# TM4C123BH6ZRB register map
Vendor: Texas Instruments; Series: TM4C; File version: 11073
CPU: CM4 r1p2, little endian, MPU, FPU, 3 interrupt priority bits
Registers are 32-bit, read-write, no defined reset value unless marked. A register's access mark holds for its fields unless they carry their own. Offsets are from the block's base; [hi:lo] are bit positions.

## WATCHDOG0 — Register map for WATCHDOG0 peripheral
Base 0x40000000; register names take the prefix WATCHDOG0
Same registers: WATCHDOG1 0x40001000 (register names take the prefix WATCHDOG1)
0x00 LOAD — Watchdog Load
  [31:0] WDT_LOAD — Watchdog Load Value
0x04 VALUE — Watchdog Value
  [31:0] WDT_VALUE
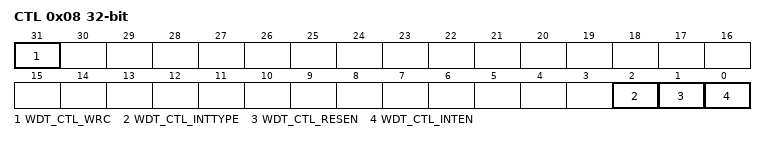
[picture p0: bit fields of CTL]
0x08 CTL — Watchdog Control
  [31] WDT_CTL_WRC — Write Complete
  [2] WDT_CTL_INTTYPE — Watchdog Interrupt Type
  [1] WDT_CTL_RESEN — Watchdog Reset Enable
  [0] WDT_CTL_INTEN — Watchdog Interrupt Enable
0x0C ICR wo — Watchdog Interrupt Clear
  [31:0] WDT_ICR
0x10 RIS — Watchdog Raw Interrupt Status
  [0] WDT_RIS_WDTRIS
0x14 MIS — Watchdog Masked Interrupt Status
  [0] WDT_MIS_WDTMIS
0x418 TEST — Watchdog Test
  [8] WDT_TEST_STALL — Watchdog Stall Enable
0xC00 LOCK — Watchdog Lock
  [31:0] WDT_LOCK
    0=WDT_LOCK_UNLOCKED (Unlocked); 1=WDT_LOCK_LOCKED (Locked); 0x1ACCE551=WDT_LOCK_UNLOCK (Unlocks the watchdog timer)

## GPIOA — Register map for GPIOA peripheral
Base 0x40004000; register names take the prefix GPIOA
Same registers: GPIOB 0x40005000 (register names take the prefix GPIOB), GPIOC 0x40006000 (register names take the prefix GPIOC), GPIOD 0x40007000 (register names take the prefix GPIOD), GPIOE 0x40024000 (register names take the prefix GPIOE), GPIOF 0x40025000 (register names take the prefix GPIOF), GPIOG 0x40026000 (register names take the prefix GPIOG), GPIOH 0x40027000 (register names take the prefix GPIOH), GPIOJ 0x4003D000 (register names take the prefix GPIOJ), GPIOA_AHB 0x40058000 (register names take the prefix GPIOA_AHB), GPIOB_AHB 0x40059000 (register names take the prefix GPIOB_AHB), GPIOC_AHB 0x4005A000 (register names take the prefix GPIOC_AHB), GPIOD_AHB 0x4005B000 (register names take the prefix GPIOD_AHB), GPIOE_AHB 0x4005C000 (register names take the prefix GPIOE_AHB), GPIOF_AHB 0x4005D000 (register names take the prefix GPIOF_AHB), GPIOG_AHB 0x4005E000 (register names take the prefix GPIOG_AHB), GPIOH_AHB 0x4005F000 (register names take the prefix GPIOH_AHB), GPIOJ_AHB 0x40060000 (register names take the prefix GPIOJ_AHB), GPIOK 0x40061000 (register names take the prefix GPIOK), GPIOL 0x40062000 (register names take the prefix GPIOL), GPIOM 0x40063000 (register names take the prefix GPIOM), GPION 0x40064000 (register names take the prefix GPION), GPIOP 0x40065000 (register names take the prefix GPIOP), GPIOQ 0x40066000 (register names take the prefix GPIOQ)
0x3FC DATA — GPIO Data
0x400 DIR — GPIO Direction
0x404 IS — GPIO Interrupt Sense
0x408 IBE — GPIO Interrupt Both Edges
0x40C IEV — GPIO Interrupt Event
0x410 IM — GPIO Interrupt Mask
  [7:0] GPIO_IM_GPIO — GPIO Interrupt Mask Enable
0x414 RIS — GPIO Raw Interrupt Status
  [7:0] GPIO_RIS_GPIO — GPIO Interrupt Raw Status
0x418 MIS — GPIO Masked Interrupt Status
  [7:0] GPIO_MIS_GPIO
0x41C ICR wo — GPIO Interrupt Clear
  [7:0] GPIO_ICR_GPIO
0x420 AFSEL — GPIO Alternate Function Select
0x500 DR2R — GPIO 2-mA Drive Select
0x504 DR4R — GPIO 4-mA Drive Select
0x508 DR8R — GPIO 8-mA Drive Select
0x50C ODR — GPIO Open Drain Select
0x510 PUR — GPIO Pull-Up Select
0x514 PDR — GPIO Pull-Down Select
0x518 SLR — GPIO Slew Rate Control Select
0x51C DEN — GPIO Digital Enable
0x520 LOCK — GPIO Lock
  [31:0] GPIO_LOCK
    0=GPIO_LOCK_UNLOCKED (The GPIOCR register is unlocked and may be modified); 1=GPIO_LOCK_LOCKED (The GPIOCR register is locked and may not be modified); 0x4C4F434B=GPIO_LOCK_KEY (Unlocks the GPIO_CR register)
0x524 CR ro — GPIO Commit
0x528 AMSEL — GPIO Analog Mode Select
0x52C PCTL — GPIO Port Control
0x530 ADCCTL — GPIO ADC Control
0x534 DMACTL — GPIO DMA Control
0x538 SI — GPIO Select Interrupt
  [0] GPIO_SI_SUM — Summary Interrupt

## Notices in the file
Software License Agreement
Texas Instruments (TI) is supplying this software for use solely and
exclusively on TI's microcontroller products. The software is owned by
TI and/or its suppliers, and is protected under applicable copyright
laws. You may not combine this software with "viral" open-source
software in order to form a larger program.
THIS SOFTWARE IS PROVIDED "AS IS" AND WITH ALL FAULTS.
NO WARRANTIES, WHETHER EXPRESS, IMPLIED OR STATUTORY, INCLUDING, BUT
NOT LIMITED TO, IMPLIED WARRANTIES OF MERCHANTABILITY AND FITNESS FOR
A PARTICULAR PURPOSE APPLY TO THIS SOFTWARE. TI SHALL NOT, UNDER ANY
CIRCUMSTANCES, BE LIABLE FOR SPECIAL, INCIDENTAL, OR CONSEQUENTIAL
DAMAGES, FOR ANY REASON WHATSOEVER.
